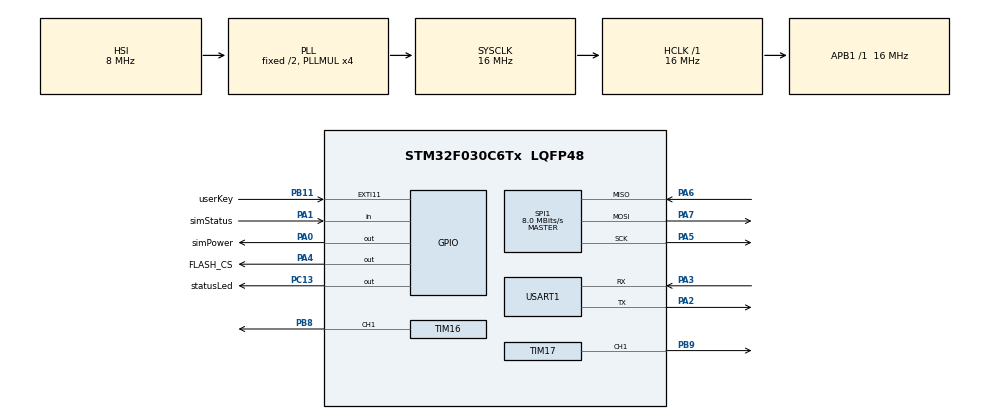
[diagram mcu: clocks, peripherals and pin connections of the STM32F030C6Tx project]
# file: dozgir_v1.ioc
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Dma.Request0=SPI1_RX
Dma.Request1=SPI1_TX
Dma.Request2=TIM16_CH1/UP
Dma.Request3=TIM17_CH1/UP
Dma.SPI1_RX.0.Direction=DMA_PERIPH_TO_MEMORY
Dma.SPI1_RX.0.Instance=DMA1_Channel2
Dma.SPI1_RX.0.MemDataAlignment=DMA_MDATAALIGN_BYTE
Dma.SPI1_RX.0.MemInc=DMA_MINC_ENABLE
Dma.SPI1_RX.0.Mode=DMA_NORMAL
Dma.SPI1_RX.0.PeriphDataAlignment=DMA_PDATAALIGN_BYTE
Dma.SPI1_RX.0.PeriphInc=DMA_PINC_DISABLE
Dma.SPI1_RX.0.Priority=DMA_PRIORITY_LOW
Dma.SPI1_TX.1.Direction=DMA_MEMORY_TO_PERIPH
Dma.SPI1_TX.1.Instance=DMA1_Channel3
Dma.SPI1_TX.1.MemDataAlignment=DMA_MDATAALIGN_BYTE
Dma.SPI1_TX.1.MemInc=DMA_MINC_DISABLE
Dma.SPI1_TX.1.Mode=DMA_NORMAL
Dma.SPI1_TX.1.PeriphDataAlignment=DMA_PDATAALIGN_BYTE
Dma.SPI1_TX.1.PeriphInc=DMA_PINC_DISABLE
Dma.SPI1_TX.1.Priority=DMA_PRIORITY_LOW
Dma.TIM16_CH1/UP.2.Direction=DMA_MEMORY_TO_PERIPH
Dma.TIM16_CH1/UP.2.Instance=DMA1_Channel4
Dma.TIM16_CH1/UP.2.MemDataAlignment=DMA_MDATAALIGN_BYTE
Dma.TIM16_CH1/UP.2.MemInc=DMA_MINC_ENABLE
Dma.TIM16_CH1/UP.2.Mode=DMA_CIRCULAR
Dma.TIM16_CH1/UP.2.PeriphDataAlignment=DMA_PDATAALIGN_HALFWORD
Dma.TIM16_CH1/UP.2.PeriphInc=DMA_PINC_DISABLE
Dma.TIM16_CH1/UP.2.Priority=DMA_PRIORITY_LOW
Dma.TIM17_CH1/UP.3.Direction=DMA_MEMORY_TO_PERIPH
Dma.TIM17_CH1/UP.3.Instance=DMA1_Channel1
Dma.TIM17_CH1/UP.3.MemDataAlignment=DMA_MDATAALIGN_BYTE
Dma.TIM17_CH1/UP.3.MemInc=DMA_MINC_ENABLE
Dma.TIM17_CH1/UP.3.Mode=DMA_CIRCULAR
Dma.TIM17_CH1/UP.3.PeriphDataAlignment=DMA_PDATAALIGN_HALFWORD
Dma.TIM17_CH1/UP.3.PeriphInc=DMA_PINC_DISABLE
Dma.TIM17_CH1/UP.3.Priority=DMA_PRIORITY_LOW
Mcu.Family=STM32F0
Mcu.Name=STM32F030C6Tx
Mcu.Package=LQFP48
NVIC.DMA1_Channel1_IRQn=true\:0\:0\:false\:false\:true\:false\:true
NVIC.DMA1_Channel2_3_IRQn=true\:0\:0\:false\:false\:true\:false\:true
NVIC.DMA1_Channel4_5_IRQn=true\:0\:0\:false\:false\:true\:false\:true
NVIC.EXTI4_15_IRQn=true\:0\:0\:false\:false\:true\:true\:true
NVIC.TIM16_IRQn=true\:1\:0\:true\:false\:true\:true\:true
NVIC.TIM17_IRQn=true\:1\:0\:true\:false\:true\:true\:true
PA0.GPIO_Label=simPower
PA0.GPIO_ModeDefaultOutputPP=GPIO_MODE_OUTPUT_OD
PA0.PinState=GPIO_PIN_SET
PA0.Signal=GPIO_Output
PA1.GPIO_Label=simStatus
PA1.GPIO_PuPd=GPIO_PULLDOWN
PA1.Signal=GPIO_Input
PA2.GPIO_PuPd=GPIO_NOPULL
PA2.Mode=Asynchronous
PA2.Signal=USART1_TX
PA3.Mode=Asynchronous
PA3.Signal=USART1_RX
PA4.GPIO_Label=FLASH_CS
PA4.Signal=GPIO_Output
PA5.Mode=Full_Duplex_Master
PA5.Signal=SPI1_SCK
PA6.Mode=Full_Duplex_Master
PA6.Signal=SPI1_MISO
PA7.Mode=Full_Duplex_Master
PA7.Signal=SPI1_MOSI
PB11.GPIO_Label=userKey
PB11.GPIO_ModeDefaultEXTI=GPIO_MODE_IT_RISING_FALLING
PB11.Signal=GPXTI11
PB8.Signal=S_TIM16_CH1
PB9.Signal=S_TIM17_CH1
PC13.GPIO_Label=statusLed
PC13.Signal=GPIO_Output
ProjectManager.HeapSize=0x100
ProjectManager.StackSize=0x200
ProjectManager.TargetToolchain=STM32CubeIDE
RCC.AHBFreq_Value=16000000
RCC.APB1Freq_Value=16000000
RCC.APB1TimFreq_Value=16000000
RCC.HCLKFreq_Value=16000000
RCC.PLLMUL=RCC_PLL_MUL4
RCC.SYSCLKFreq_VALUE=16000000
RCC.SYSCLKSource=RCC_SYSCLKSOURCE_PLLCLK
SH.S_TIM16_CH1.0=TIM16_CH1,PWM Generation1 CH1
SH.S_TIM17_CH1.0=TIM17_CH1,PWM Generation1 CH1
SPI1.CLKPolarity=SPI_POLARITY_LOW
SPI1.CalculateBaudRate=8.0 MBits/s
SPI1.DataSize=SPI_DATASIZE_8BIT
SPI1.Direction=SPI_DIRECTION_2LINES
SPI1.Mode=SPI_MODE_MASTER
SPI1.VirtualType=VM_MASTER
TIM16.Channel=TIM_CHANNEL_1
TIM16.Period=256-1
TIM16.Prescaler=2-1
TIM17.Channel=TIM_CHANNEL_1
TIM17.Period=256-1
TIM17.Prescaler=2-1
USART1.VirtualMode-Asynchronous=VM_ASYNC
VP_TIM16_VS_ClockSourceINT.Mode=Enable_Timer
VP_TIM17_VS_ClockSourceINT.Mode=Enable_Timer
board=custom

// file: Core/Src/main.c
/* USER CODE BEGIN Header */
/**
  ******************************************************************************
  * @file           : main.c
  * @brief          : Main program body
  ******************************************************************************
  * @attention
  *
  * <h2><center>&copy; Copyright (c) 2021 STMicroelectronics.
  * All rights reserved.</center></h2>
  *
  * This software component is licensed by ST under BSD 3-Clause license,
  * the "License"; You may not use this file except in compliance with the
  * License. You may obtain a copy of the License at:
  *                        opensource.org/licenses/BSD-3-Clause
  *
  ******************************************************************************
  */
/* USER CODE END Header */
#include "main.h"

/* USER CODE BEGIN Includes */
#include "mainCodes.h"
/* USER CODE END Includes */

SPI_HandleTypeDef hspi1;
DMA_HandleTypeDef hdma_spi1_rx;
DMA_HandleTypeDef hdma_spi1_tx;

TIM_HandleTypeDef htim16;
TIM_HandleTypeDef htim17;
DMA_HandleTypeDef hdma_tim16_ch1_up;
DMA_HandleTypeDef hdma_tim17_ch1_up;

UART_HandleTypeDef huart1;

void SystemClock_Config(void);
static void MX_GPIO_Init(void);
static void MX_DMA_Init(void);
static void MX_USART1_UART_Init(void);
static void MX_TIM16_Init(void);
static void MX_TIM17_Init(void);
static void MX_SPI1_Init(void);

int main(void)
{

  /* MCU Configuration--------------------------------------------------------*/

  /* Reset of all peripherals, Initializes the Flash interface and the Systick. */
  HAL_Init();

  /* Configure the system clock */
  SystemClock_Config();

  /* Initialize all configured peripherals */
  MX_GPIO_Init();
  MX_DMA_Init();
  MX_USART1_UART_Init();
  MX_TIM16_Init();
  MX_TIM17_Init();
  MX_SPI1_Init();
  /* USER CODE BEGIN 2 */
  setup();
  /* USER CODE END 2 */

  /* Infinite loop */
  /* USER CODE BEGIN WHILE */
  while (1)
  {

	loop();
    /* USER CODE END WHILE */

  }
}

void SystemClock_Config(void)
{
  RCC_OscInitTypeDef RCC_OscInitStruct = {0};
  RCC_ClkInitTypeDef RCC_ClkInitStruct = {0};
  RCC_PeriphCLKInitTypeDef PeriphClkInit = {0};

  /** Initializes the RCC Oscillators according to the specified parameters
  * in the RCC_OscInitTypeDef structure.
  */
  RCC_OscInitStruct.OscillatorType = RCC_OSCILLATORTYPE_HSI;
  RCC_OscInitStruct.HSIState = RCC_HSI_ON;
  RCC_OscInitStruct.HSICalibrationValue = RCC_HSICALIBRATION_DEFAULT;
  RCC_OscInitStruct.PLL.PLLState = RCC_PLL_ON;
  RCC_OscInitStruct.PLL.PLLSource = RCC_PLLSOURCE_HSI;
  RCC_OscInitStruct.PLL.PLLMUL = RCC_PLL_MUL4;
  RCC_OscInitStruct.PLL.PREDIV = RCC_PREDIV_DIV1;
  if (HAL_RCC_OscConfig(&RCC_OscInitStruct) != HAL_OK)
  {
    Error_Handler();
  }
  /** Initializes the CPU, AHB and APB buses clocks
  */
  RCC_ClkInitStruct.ClockType = RCC_CLOCKTYPE_HCLK|RCC_CLOCKTYPE_SYSCLK
                              |RCC_CLOCKTYPE_PCLK1;
  RCC_ClkInitStruct.SYSCLKSource = RCC_SYSCLKSOURCE_PLLCLK;
  RCC_ClkInitStruct.AHBCLKDivider = RCC_SYSCLK_DIV1;
  RCC_ClkInitStruct.APB1CLKDivider = RCC_HCLK_DIV1;

  if (HAL_RCC_ClockConfig(&RCC_ClkInitStruct, FLASH_LATENCY_0) != HAL_OK)
  {
    Error_Handler();
  }
  PeriphClkInit.PeriphClockSelection = RCC_PERIPHCLK_USART1;
  PeriphClkInit.Usart1ClockSelection = RCC_USART1CLKSOURCE_PCLK1;
  if (HAL_RCCEx_PeriphCLKConfig(&PeriphClkInit) != HAL_OK)
  {
    Error_Handler();
  }
}

static void MX_SPI1_Init(void)
{

  /* SPI1 parameter configuration*/
  hspi1.Instance = SPI1;
  hspi1.Init.Mode = SPI_MODE_MASTER;
  hspi1.Init.Direction = SPI_DIRECTION_2LINES;
  hspi1.Init.DataSize = SPI_DATASIZE_8BIT;
  hspi1.Init.CLKPolarity = SPI_POLARITY_LOW;
  hspi1.Init.CLKPhase = SPI_PHASE_1EDGE;
  hspi1.Init.NSS = SPI_NSS_SOFT;
  hspi1.Init.BaudRatePrescaler = SPI_BAUDRATEPRESCALER_2;
  hspi1.Init.FirstBit = SPI_FIRSTBIT_MSB;
  hspi1.Init.TIMode = SPI_TIMODE_DISABLE;
  hspi1.Init.CRCCalculation = SPI_CRCCALCULATION_DISABLE;
  hspi1.Init.CRCPolynomial = 7;
  hspi1.Init.CRCLength = SPI_CRC_LENGTH_DATASIZE;
  hspi1.Init.NSSPMode = SPI_NSS_PULSE_ENABLE;
  if (HAL_SPI_Init(&hspi1) != HAL_OK)
  {
    Error_Handler();
  }

}

static void MX_TIM16_Init(void)
{

  TIM_OC_InitTypeDef sConfigOC = {0};
  TIM_BreakDeadTimeConfigTypeDef sBreakDeadTimeConfig = {0};

  htim16.Instance = TIM16;
  htim16.Init.Prescaler = 2-1;
  htim16.Init.CounterMode = TIM_COUNTERMODE_UP;
  htim16.Init.Period = 256-1;
  htim16.Init.ClockDivision = TIM_CLOCKDIVISION_DIV1;
  htim16.Init.RepetitionCounter = 0;
  htim16.Init.AutoReloadPreload = TIM_AUTORELOAD_PRELOAD_DISABLE;
  if (HAL_TIM_Base_Init(&htim16) != HAL_OK)
  {
    Error_Handler();
  }
  if (HAL_TIM_PWM_Init(&htim16) != HAL_OK)
  {
    Error_Handler();
  }
  sConfigOC.OCMode = TIM_OCMODE_PWM1;
  sConfigOC.Pulse = 0;
  sConfigOC.OCPolarity = TIM_OCPOLARITY_HIGH;
  sConfigOC.OCNPolarity = TIM_OCNPOLARITY_HIGH;
  sConfigOC.OCFastMode = TIM_OCFAST_DISABLE;
  sConfigOC.OCIdleState = TIM_OCIDLESTATE_RESET;
  sConfigOC.OCNIdleState = TIM_OCNIDLESTATE_RESET;
  if (HAL_TIM_PWM_ConfigChannel(&htim16, &sConfigOC, TIM_CHANNEL_1) != HAL_OK)
  {
    Error_Handler();
  }
  sBreakDeadTimeConfig.OffStateRunMode = TIM_OSSR_DISABLE;
  sBreakDeadTimeConfig.OffStateIDLEMode = TIM_OSSI_DISABLE;
  sBreakDeadTimeConfig.LockLevel = TIM_LOCKLEVEL_OFF;
  sBreakDeadTimeConfig.DeadTime = 0;
  sBreakDeadTimeConfig.BreakState = TIM_BREAK_DISABLE;
  sBreakDeadTimeConfig.BreakPolarity = TIM_BREAKPOLARITY_HIGH;
  sBreakDeadTimeConfig.AutomaticOutput = TIM_AUTOMATICOUTPUT_DISABLE;
  if (HAL_TIMEx_ConfigBreakDeadTime(&htim16, &sBreakDeadTimeConfig) != HAL_OK)
  {
    Error_Handler();
  }
  HAL_TIM_MspPostInit(&htim16);

}

static void MX_TIM17_Init(void)
{

  TIM_OC_InitTypeDef sConfigOC = {0};
  TIM_BreakDeadTimeConfigTypeDef sBreakDeadTimeConfig = {0};

  htim17.Instance = TIM17;
  htim17.Init.Prescaler = 2-1;
  htim17.Init.CounterMode = TIM_COUNTERMODE_UP;
  htim17.Init.Period = 256-1;
  htim17.Init.ClockDivision = TIM_CLOCKDIVISION_DIV1;
  htim17.Init.RepetitionCounter = 0;
  htim17.Init.AutoReloadPreload = TIM_AUTORELOAD_PRELOAD_DISABLE;
  if (HAL_TIM_Base_Init(&htim17) != HAL_OK)
  {
    Error_Handler();
  }
  if (HAL_TIM_PWM_Init(&htim17) != HAL_OK)
  {
    Error_Handler();
  }
  sConfigOC.OCMode = TIM_OCMODE_PWM1;
  sConfigOC.Pulse = 0;
  sConfigOC.OCPolarity = TIM_OCPOLARITY_HIGH;
  sConfigOC.OCNPolarity = TIM_OCNPOLARITY_HIGH;
  sConfigOC.OCFastMode = TIM_OCFAST_DISABLE;
  sConfigOC.OCIdleState = TIM_OCIDLESTATE_RESET;
  sConfigOC.OCNIdleState = TIM_OCNIDLESTATE_RESET;
  if (HAL_TIM_PWM_ConfigChannel(&htim17, &sConfigOC, TIM_CHANNEL_1) != HAL_OK)
  {
    Error_Handler();
  }
  sBreakDeadTimeConfig.OffStateRunMode = TIM_OSSR_DISABLE;
  sBreakDeadTimeConfig.OffStateIDLEMode = TIM_OSSI_DISABLE;
  sBreakDeadTimeConfig.LockLevel = TIM_LOCKLEVEL_OFF;
  sBreakDeadTimeConfig.DeadTime = 0;
  sBreakDeadTimeConfig.BreakState = TIM_BREAK_DISABLE;
  sBreakDeadTimeConfig.BreakPolarity = TIM_BREAKPOLARITY_HIGH;
  sBreakDeadTimeConfig.AutomaticOutput = TIM_AUTOMATICOUTPUT_DISABLE;
  if (HAL_TIMEx_ConfigBreakDeadTime(&htim17, &sBreakDeadTimeConfig) != HAL_OK)
  {
    Error_Handler();
  }
  HAL_TIM_MspPostInit(&htim17);

}

static void MX_USART1_UART_Init(void)
{

  huart1.Instance = USART1;
  huart1.Init.BaudRate = 38400;
  huart1.Init.WordLength = UART_WORDLENGTH_8B;
  huart1.Init.StopBits = UART_STOPBITS_1;
  huart1.Init.Parity = UART_PARITY_NONE;
  huart1.Init.Mode = UART_MODE_TX_RX;
  huart1.Init.HwFlowCtl = UART_HWCONTROL_NONE;
  huart1.Init.OverSampling = UART_OVERSAMPLING_16;
  huart1.Init.OneBitSampling = UART_ONE_BIT_SAMPLE_DISABLE;
  huart1.AdvancedInit.AdvFeatureInit = UART_ADVFEATURE_NO_INIT;
  if (HAL_UART_Init(&huart1) != HAL_OK)
  {
    Error_Handler();
  }

}

static void MX_DMA_Init(void)
{

  /* DMA controller clock enable */
  __HAL_RCC_DMA1_CLK_ENABLE();

  /* DMA interrupt init */
  /* DMA1_Channel1_IRQn interrupt configuration */
  HAL_NVIC_SetPriority(DMA1_Channel1_IRQn, 0, 0);
  HAL_NVIC_EnableIRQ(DMA1_Channel1_IRQn);
  /* DMA1_Channel2_3_IRQn interrupt configuration */
  HAL_NVIC_SetPriority(DMA1_Channel2_3_IRQn, 0, 0);
  HAL_NVIC_EnableIRQ(DMA1_Channel2_3_IRQn);
  /* DMA1_Channel4_5_IRQn interrupt configuration */
  HAL_NVIC_SetPriority(DMA1_Channel4_5_IRQn, 0, 0);
  HAL_NVIC_EnableIRQ(DMA1_Channel4_5_IRQn);

}

static void MX_GPIO_Init(void)
{
  GPIO_InitTypeDef GPIO_InitStruct = {0};

  /* GPIO Ports Clock Enable */
  __HAL_RCC_GPIOC_CLK_ENABLE();
  __HAL_RCC_GPIOA_CLK_ENABLE();
  __HAL_RCC_GPIOB_CLK_ENABLE();

  /*Configure GPIO pin Output Level */
  HAL_GPIO_WritePin(statusLed_GPIO_Port, statusLed_Pin, GPIO_PIN_RESET);

  /*Configure GPIO pin Output Level */
  HAL_GPIO_WritePin(simPower_GPIO_Port, simPower_Pin, GPIO_PIN_SET);

  /*Configure GPIO pin Output Level */
  HAL_GPIO_WritePin(FLASH_CS_GPIO_Port, FLASH_CS_Pin, GPIO_PIN_RESET);

  /*Configure GPIO pin : statusLed_Pin */
  GPIO_InitStruct.Pin = statusLed_Pin;
  GPIO_InitStruct.Mode = GPIO_MODE_OUTPUT_PP;
  GPIO_InitStruct.Pull = GPIO_NOPULL;
  GPIO_InitStruct.Speed = GPIO_SPEED_FREQ_LOW;
  HAL_GPIO_Init(statusLed_GPIO_Port, &GPIO_InitStruct);

  /*Configure GPIO pin : simPower_Pin */
  GPIO_InitStruct.Pin = simPower_Pin;
  GPIO_InitStruct.Mode = GPIO_MODE_OUTPUT_OD;
  GPIO_InitStruct.Pull = GPIO_NOPULL;
  GPIO_InitStruct.Speed = GPIO_SPEED_FREQ_LOW;
  HAL_GPIO_Init(simPower_GPIO_Port, &GPIO_InitStruct);

  /*Configure GPIO pin : simStatus_Pin */
  GPIO_InitStruct.Pin = simStatus_Pin;
  GPIO_InitStruct.Mode = GPIO_MODE_INPUT;
  GPIO_InitStruct.Pull = GPIO_PULLDOWN;
  HAL_GPIO_Init(simStatus_GPIO_Port, &GPIO_InitStruct);

  /*Configure GPIO pin : FLASH_CS_Pin */
  GPIO_InitStruct.Pin = FLASH_CS_Pin;
  GPIO_InitStruct.Mode = GPIO_MODE_OUTPUT_PP;
  GPIO_InitStruct.Pull = GPIO_NOPULL;
  GPIO_InitStruct.Speed = GPIO_SPEED_FREQ_LOW;
  HAL_GPIO_Init(FLASH_CS_GPIO_Port, &GPIO_InitStruct);

  /*Configure GPIO pin : userKey_Pin */
  GPIO_InitStruct.Pin = userKey_Pin;
  GPIO_InitStruct.Mode = GPIO_MODE_IT_RISING_FALLING;
  GPIO_InitStruct.Pull = GPIO_NOPULL;
  HAL_GPIO_Init(userKey_GPIO_Port, &GPIO_InitStruct);

  /* EXTI interrupt init*/
  HAL_NVIC_SetPriority(EXTI4_15_IRQn, 0, 0);
  HAL_NVIC_EnableIRQ(EXTI4_15_IRQn);

}

void Error_Handler(void)
{
}

/************************ (C) COPYRIGHT STMicroelectronics *****END OF FILE****/
